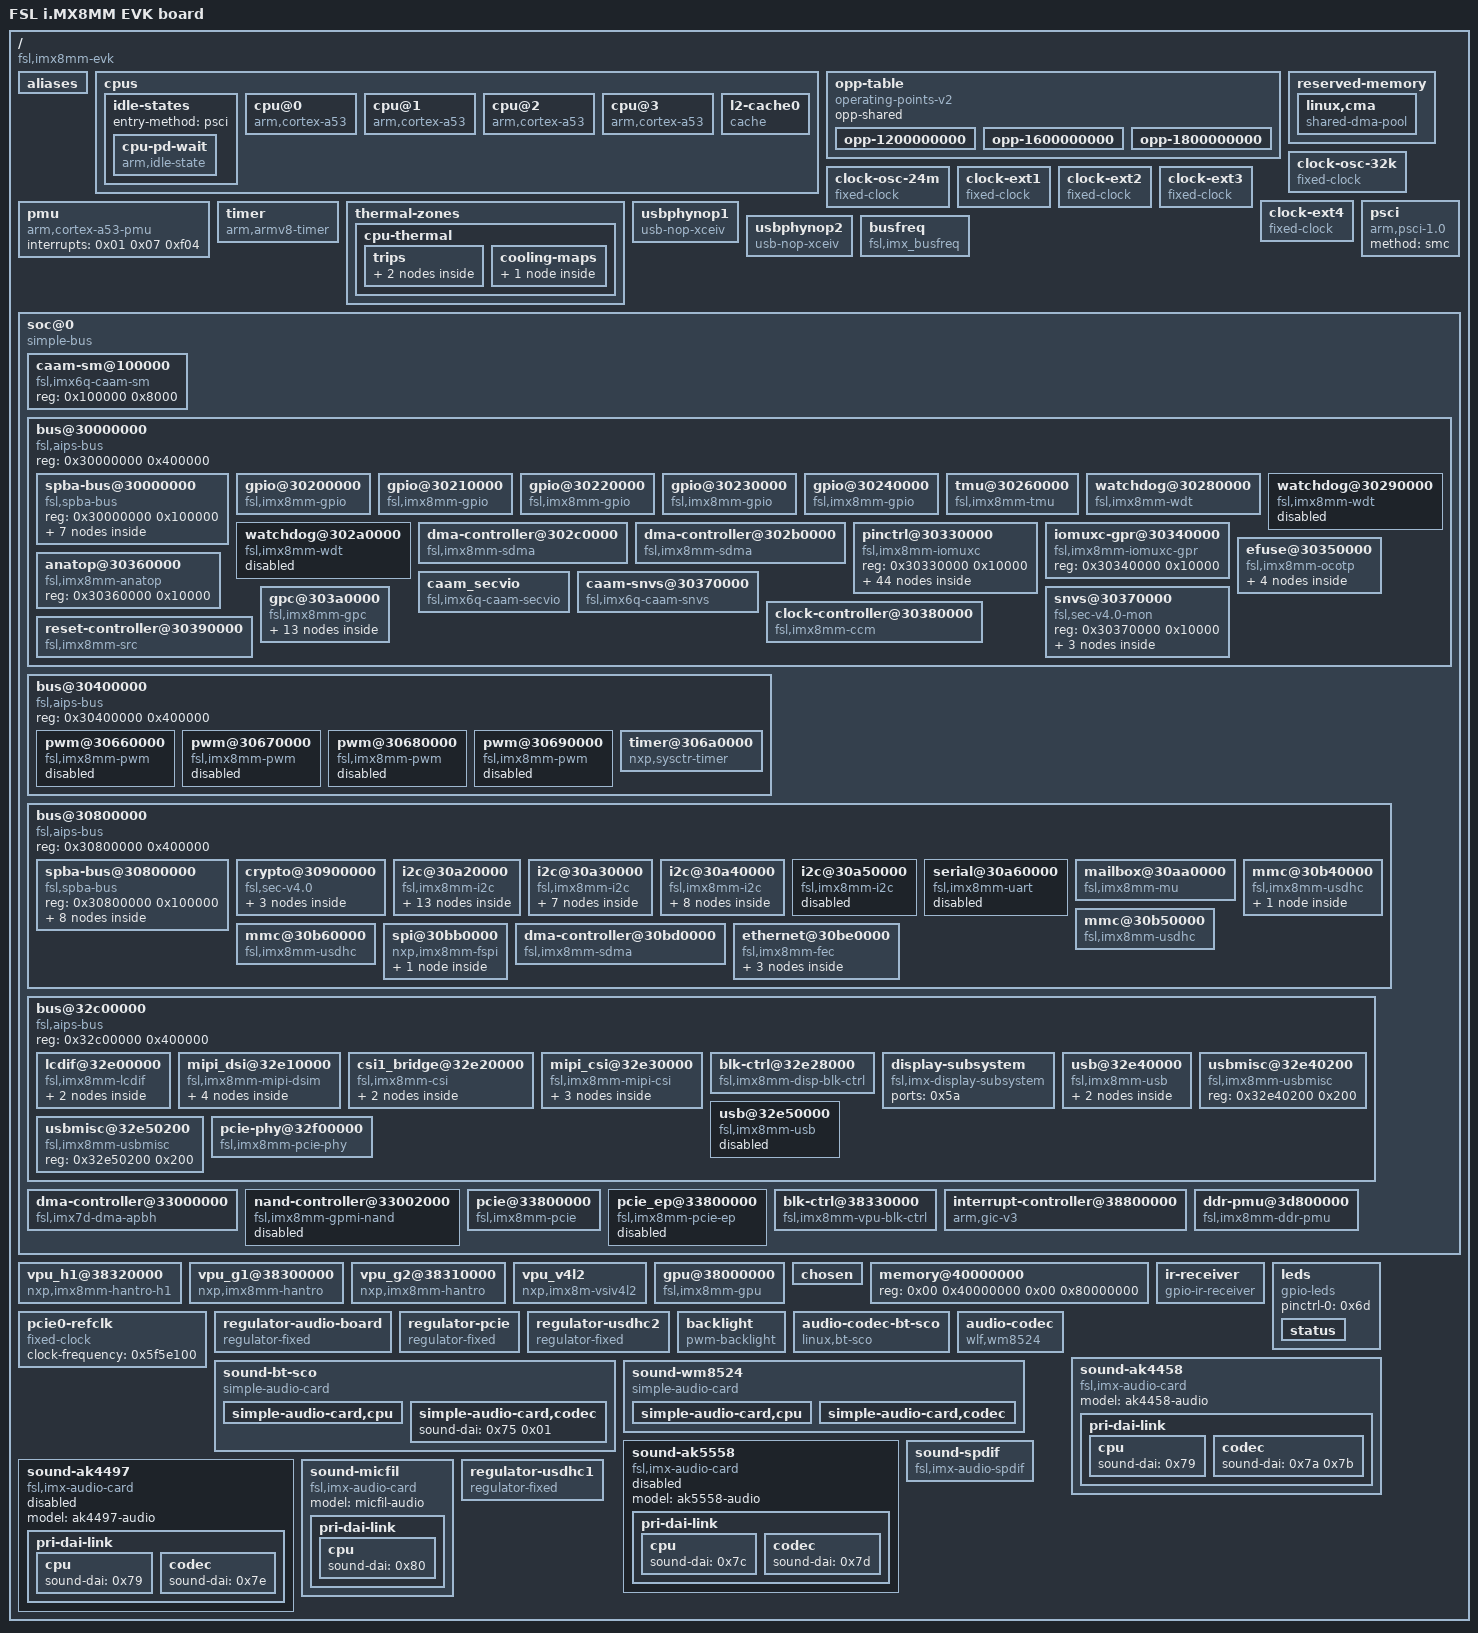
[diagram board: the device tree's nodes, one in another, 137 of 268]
/dts-v1/;

/ {
	interrupt-parent = <0x01>;
	#address-cells = <0x02>;
	#size-cells = <0x02>;
	model = "FSL i.MX8MM EVK board";
	compatible = "fsl,imx8mm-evk", "fsl,imx8mm";

	aliases {
		ethernet0 = "/soc@0/bus@30800000/ethernet@30be0000";
		gpio0 = "/soc@0/bus@30000000/gpio@30200000";
		gpio1 = "/soc@0/bus@30000000/gpio@30210000";
		gpio2 = "/soc@0/bus@30000000/gpio@30220000";
		gpio3 = "/soc@0/bus@30000000/gpio@30230000";
		gpio4 = "/soc@0/bus@30000000/gpio@30240000";
		i2c0 = "/soc@0/bus@30800000/i2c@30a20000";
		i2c1 = "/soc@0/bus@30800000/i2c@30a30000";
		i2c2 = "/soc@0/bus@30800000/i2c@30a40000";
		i2c3 = "/soc@0/bus@30800000/i2c@30a50000";
		mmc0 = "/soc@0/bus@30800000/mmc@30b40000";
		mmc1 = "/soc@0/bus@30800000/mmc@30b50000";
		mmc2 = "/soc@0/bus@30800000/mmc@30b60000";
		sai1 = "/soc@0/bus@30000000/spba-bus@30000000/sai@30010000";
		sai2 = "/soc@0/bus@30000000/spba-bus@30000000/sai@30020000";
		sai3 = "/soc@0/bus@30000000/spba-bus@30000000/sai@30030000";
		sai5 = "/soc@0/bus@30000000/spba-bus@30000000/sai@30050000";
		sai6 = "/soc@0/bus@30000000/spba-bus@30000000/sai@30060000";
		serial0 = "/soc@0/bus@30800000/spba-bus@30800000/serial@30860000";
		serial1 = "/soc@0/bus@30800000/spba-bus@30800000/serial@30890000";
		serial2 = "/soc@0/bus@30800000/spba-bus@30800000/serial@30880000";
		serial3 = "/soc@0/bus@30800000/serial@30a60000";
		spi0 = "/soc@0/bus@30800000/spi@30bb0000";
		spi1 = "/soc@0/bus@30800000/spba-bus@30800000/spi@30830000";
		spi2 = "/soc@0/bus@30800000/spba-bus@30800000/spi@30840000";
	};

	cpus {
		#address-cells = <0x01>;
		#size-cells = <0x00>;

		idle-states {
			entry-method = "psci";

			cpu-pd-wait {
				compatible = "arm,idle-state";
				arm,psci-suspend-param = <0x10033>;
				local-timer-stop;
				entry-latency-us = <0x3e8>;
				exit-latency-us = <0x2bc>;
				min-residency-us = <0xa8c>;
				phandle = <0x06>;
			};
		};

		cpu@0 {
			device_type = "cpu";
			compatible = "arm,cortex-a53";
			reg = <0x00>;
			clock-latency = <0xee6c>;
			clocks = <0x02 0xd7>;
			enable-method = "psci";
			i-cache-size = <0x8000>;
			i-cache-line-size = <0x40>;
			i-cache-sets = <0x100>;
			d-cache-size = <0x8000>;
			d-cache-line-size = <0x40>;
			d-cache-sets = <0x80>;
			next-level-cache = <0x03>;
			operating-points-v2 = <0x04>;
			nvmem-cells = <0x05>;
			nvmem-cell-names = "speed_grade";
			cpu-idle-states = <0x06>;
			#cooling-cells = <0x02>;
			cpu-supply = <0x07>;
			phandle = <0x0a>;
		};

		cpu@1 {
			device_type = "cpu";
			compatible = "arm,cortex-a53";
			reg = <0x01>;
			clock-latency = <0xee6c>;
			clocks = <0x02 0xd7>;
			enable-method = "psci";
			i-cache-size = <0x8000>;
			i-cache-line-size = <0x40>;
			i-cache-sets = <0x100>;
			d-cache-size = <0x8000>;
			d-cache-line-size = <0x40>;
			d-cache-sets = <0x80>;
			next-level-cache = <0x03>;
			operating-points-v2 = <0x04>;
			cpu-idle-states = <0x06>;
			#cooling-cells = <0x02>;
			cpu-supply = <0x07>;
			phandle = <0x0b>;
		};

		cpu@2 {
			device_type = "cpu";
			compatible = "arm,cortex-a53";
			reg = <0x02>;
			clock-latency = <0xee6c>;
			clocks = <0x02 0xd7>;
			enable-method = "psci";
			i-cache-size = <0x8000>;
			i-cache-line-size = <0x40>;
			i-cache-sets = <0x100>;
			d-cache-size = <0x8000>;
			d-cache-line-size = <0x40>;
			d-cache-sets = <0x80>;
			next-level-cache = <0x03>;
			operating-points-v2 = <0x04>;
			cpu-idle-states = <0x06>;
			#cooling-cells = <0x02>;
			cpu-supply = <0x07>;
			phandle = <0x0c>;
		};

		cpu@3 {
			device_type = "cpu";
			compatible = "arm,cortex-a53";
			reg = <0x03>;
			clock-latency = <0xee6c>;
			clocks = <0x02 0xd7>;
			enable-method = "psci";
			i-cache-size = <0x8000>;
			i-cache-line-size = <0x40>;
			i-cache-sets = <0x100>;
			d-cache-size = <0x8000>;
			d-cache-line-size = <0x40>;
			d-cache-sets = <0x80>;
			next-level-cache = <0x03>;
			operating-points-v2 = <0x04>;
			cpu-idle-states = <0x06>;
			#cooling-cells = <0x02>;
			cpu-supply = <0x07>;
			phandle = <0x0d>;
		};

		l2-cache0 {
			compatible = "cache";
			cache-level = <0x02>;
			cache-size = <0x80000>;
			cache-line-size = <0x40>;
			cache-sets = <0x200>;
			phandle = <0x03>;
		};
	};

	opp-table {
		compatible = "operating-points-v2";
		opp-shared;
		phandle = <0x04>;

		opp-1200000000 {
			opp-hz = <0x00 0x47868c00>;
			opp-microvolt = <0xcf850>;
			opp-supported-hw = <0x0e 0x07>;
			clock-latency-ns = <0x249f0>;
			opp-suspend;
		};

		opp-1600000000 {
			opp-hz = <0x00 0x5f5e1000>;
			opp-microvolt = <0xe7ef0>;
			opp-supported-hw = <0x0c 0x07>;
			clock-latency-ns = <0x249f0>;
			opp-suspend;
		};

		opp-1800000000 {
			opp-hz = <0x00 0x6b49d200>;
			opp-microvolt = <0xf4240>;
			opp-supported-hw = <0x08 0x03>;
			clock-latency-ns = <0x249f0>;
			opp-suspend;
		};
	};

	reserved-memory {
		#address-cells = <0x02>;
		#size-cells = <0x02>;
		ranges;

		linux,cma {
			compatible = "shared-dma-pool";
			reusable;
			size = <0x00 0x28000000>;
			alloc-ranges = <0x00 0x80000000 0x00 0x40000000>;
			linux,cma-default;
		};
	};

	clock-osc-32k {
		compatible = "fixed-clock";
		#clock-cells = <0x00>;
		clock-frequency = <0x8000>;
		clock-output-names = "osc_32k";
		phandle = <0x1c>;
	};

	clock-osc-24m {
		compatible = "fixed-clock";
		#clock-cells = <0x00>;
		clock-frequency = <0x16e3600>;
		clock-output-names = "osc_24m";
		phandle = <0x1d>;
	};

	clock-ext1 {
		compatible = "fixed-clock";
		#clock-cells = <0x00>;
		clock-frequency = <0x7ed6b40>;
		clock-output-names = "clk_ext1";
		phandle = <0x1e>;
	};

	clock-ext2 {
		compatible = "fixed-clock";
		#clock-cells = <0x00>;
		clock-frequency = <0x7ed6b40>;
		clock-output-names = "clk_ext2";
		phandle = <0x1f>;
	};

	clock-ext3 {
		compatible = "fixed-clock";
		#clock-cells = <0x00>;
		clock-frequency = <0x7ed6b40>;
		clock-output-names = "clk_ext3";
		phandle = <0x20>;
	};

	clock-ext4 {
		compatible = "fixed-clock";
		#clock-cells = <0x00>;
		clock-frequency = <0x7ed6b40>;
		clock-output-names = "clk_ext4";
		phandle = <0x21>;
	};

	psci {
		compatible = "arm,psci-1.0";
		method = "smc";
	};

	pmu {
		compatible = "arm,cortex-a53-pmu";
		interrupts = <0x01 0x07 0xf04>;
	};

	timer {
		compatible = "arm,armv8-timer";
		interrupts = <0x01 0x0d 0xf08 0x01 0x0e 0xf08 0x01 0x0b 0xf08 0x01 0x0a 0xf08>;
		clock-frequency = <0x7a1200>;
		arm,no-tick-in-suspend;
	};

	thermal-zones {

		cpu-thermal {
			polling-delay-passive = <0xfa>;
			polling-delay = <0x7d0>;
			thermal-sensors = <0x08>;

			trips {

				trip0 {
					temperature = <0x14c08>;
					hysteresis = <0x7d0>;
					type = "passive";
					phandle = <0x09>;
				};

				trip1 {
					temperature = <0x17318>;
					hysteresis = <0x7d0>;
					type = "critical";
				};
			};

			cooling-maps {

				map0 {
					trip = <0x09>;
					cooling-device = <0x0a 0xffffffff 0xffffffff 0x0b 0xffffffff 0xffffffff 0x0c 0xffffffff 0xffffffff 0x0d 0xffffffff 0xffffffff>;
				};
			};
		};
	};

	usbphynop1 {
		#phy-cells = <0x00>;
		compatible = "usb-nop-xceiv";
		clocks = <0x02 0x84>;
		assigned-clocks = <0x02 0x84>;
		assigned-clock-parents = <0x02 0x32>;
		clock-names = "main_clk";
		power-domains = <0x0e>;
		wakeup-source;
		phandle = <0x5b>;
	};

	usbphynop2 {
		#phy-cells = <0x00>;
		compatible = "usb-nop-xceiv";
		clocks = <0x02 0x84>;
		assigned-clocks = <0x02 0x84>;
		assigned-clock-parents = <0x02 0x32>;
		clock-names = "main_clk";
		power-domains = <0x0f>;
		wakeup-source;
		phandle = <0x5e>;
	};

	busfreq {
		compatible = "fsl,imx_busfreq";
		clocks = <0x02 0x29 0x02 0x61 0x02 0x62 0x02 0x62 0x02 0xdc 0x02 0xdd 0x02 0x30 0x02 0x32 0x02 0x3f 0x02 0x5b 0x02 0x5d 0x02 0x51 0x02 0x02 0x02 0x38 0x02 0x15>;
		clock-names = "dram_pll", "dram_alt_src", "dram_apb_src", "dram_apb_pre_div", "dram_core", "dram_alt_root", "sys_pll1_40m", "sys_pll1_100m", "sys_pll2_333m", "noc_div", "ahb_div", "main_axi_src", "osc_24m", "sys_pll1_800m", "dram_pll_div";
		interrupts = <0x00 0x4a 0x04 0x00 0x4b 0x04 0x00 0x4c 0x04 0x00 0x4d 0x04>;
		interrupt-name = "irq_busfreq_0", "irq_busfreq_1", "irq_busfreq_2", "irq_busfreq_3";
	};

	soc@0 {
		compatible = "simple-bus";
		#address-cells = <0x01>;
		#size-cells = <0x01>;
		ranges = <0x00 0x00 0x00 0x3e000000>;
		dma-ranges = <0x40000000 0x00 0x40000000 0xc0000000>;
		nvmem-cells = <0x10>;
		nvmem-cell-names = "soc_unique_id";

		caam-sm@100000 {
			compatible = "fsl,imx6q-caam-sm";
			reg = <0x100000 0x8000>;
		};

		bus@30000000 {
			compatible = "fsl,aips-bus", "simple-bus";
			reg = <0x30000000 0x400000>;
			#address-cells = <0x01>;
			#size-cells = <0x01>;
			ranges = <0x30000000 0x30000000 0x400000>;

			spba-bus@30000000 {
				compatible = "fsl,spba-bus", "simple-bus";
				#address-cells = <0x01>;
				#size-cells = <0x01>;
				reg = <0x30000000 0x100000>;
				ranges;

				sai@30010000 {
					#sound-dai-cells = <0x00>;
					compatible = "fsl,imx8mm-sai", "fsl,imx8mq-sai";
					reg = <0x30010000 0x10000>;
					interrupts = <0x00 0x5f 0x04>;
					clocks = <0x02 0xb1 0x02 0x00 0x02 0xb0 0x02 0x00 0x02 0x00 0x02 0x26 0x02 0x27>;
					clock-names = "bus", "mclk0", "mclk1", "mclk2", "mclk3", "pll8k", "pll11k";
					dmas = <0x11 0x00 0x19 0x00 0x11 0x01 0x19 0x00>;
					dma-names = "rx", "tx";
					fsl,dataline = <0x00 0xff 0xff 0x02 0xff 0x11>;
					status = "okay";
					pinctrl-names = "default", "dsd";
					pinctrl-0 = <0x12>;
					pinctrl-1 = <0x13>;
					assigned-clocks = <0x02 0x6c>;
					assigned-clock-parents = <0x02 0x26>;
					assigned-clock-rates = <0x2ee0000>;
					fsl,sai-multi-lane;
					fsl,sai-mclk-direction-output;
					phandle = <0x79>;
				};

				sai@30020000 {
					#sound-dai-cells = <0x00>;
					compatible = "fsl,imx8mm-sai", "fsl,imx8mq-sai";
					reg = <0x30020000 0x10000>;
					interrupts = <0x00 0x60 0x04>;
					clocks = <0x02 0xb3 0x02 0x00 0x02 0xb2 0x02 0x00 0x02 0x00>;
					clock-names = "bus", "mclk0", "mclk1", "mclk2", "mclk3";
					dmas = <0x11 0x02 0x02 0x00 0x11 0x03 0x02 0x00>;
					dma-names = "rx", "tx";
					status = "okay";
					pinctrl-names = "default";
					pinctrl-0 = <0x14>;
					assigned-clocks = <0x02 0x6d>;
					assigned-clock-parents = <0x02 0x26>;
					assigned-clock-rates = <0x1770000>;
					fsl,sai-mclk-direction-output;
					phandle = <0x74>;
				};

				sai@30030000 {
					#sound-dai-cells = <0x00>;
					compatible = "fsl,imx8mm-sai", "fsl,imx8mq-sai";
					reg = <0x30030000 0x10000>;
					interrupts = <0x00 0x32 0x04>;
					clocks = <0x02 0xb5 0x02 0x00 0x02 0xb4 0x02 0x00 0x02 0x00>;
					clock-names = "bus", "mclk0", "mclk1", "mclk2", "mclk3";
					dmas = <0x11 0x04 0x02 0x00 0x11 0x05 0x02 0x00>;
					dma-names = "rx", "tx";
					status = "okay";
					pinctrl-names = "default";
					pinctrl-0 = <0x15>;
					assigned-clocks = <0x02 0x6e>;
					assigned-clock-parents = <0x02 0x26>;
					assigned-clock-rates = <0x1770000>;
					fsl,sai-mclk-direction-output;
					phandle = <0x77>;
				};

				sai@30050000 {
					#sound-dai-cells = <0x00>;
					compatible = "fsl,imx8mm-sai", "fsl,imx8mq-sai";
					reg = <0x30050000 0x10000>;
					interrupts = <0x00 0x5a 0x04>;
					clocks = <0x02 0xb9 0x02 0x00 0x02 0xb8 0x02 0x00 0x02 0x00 0x02 0x26 0x02 0x27>;
					clock-names = "bus", "mclk0", "mclk1", "mclk2", "mclk3", "pll8k", "pll11k";
					dmas = <0x11 0x08 0x19 0x00 0x11 0x09 0x19 0x00>;
					dma-names = "rx", "tx";
					fsl,dataline = <0x00 0x0f 0x0f>;
					status = "disabled";
					pinctrl-names = "default";
					pinctrl-0 = <0x16>;
					assigned-clocks = <0x02 0x70>;
					assigned-clock-parents = <0x02 0x26>;
					assigned-clock-rates = <0x2ee0000>;
					fsl,sai-asynchronous;
					fsl,sai-multi-lane;
					fsl,sai-mclk-direction-output;
					phandle = <0x7c>;
				};

				sai@30060000 {
					#sound-dai-cells = <0x00>;
					compatible = "fsl,imx8mm-sai", "fsl,imx8mq-sai";
					reg = <0x30060000 0x10000>;
					interrupts = <0x00 0x5a 0x04>;
					clocks = <0x02 0xbb 0x02 0x00 0x02 0xba 0x02 0x00 0x02 0x00>;
					clock-names = "bus", "mclk0", "mclk1", "mclk2", "mclk3";
					dmas = <0x11 0x0a 0x02 0x00 0x11 0x0b 0x02 0x00>;
					dma-names = "rx", "tx";
					status = "okay";
					fsl,sai-monitor-spdif;
					fsl,sai-asynchronous;
				};

				audio-controller@30080000 {
					compatible = "fsl,imx8mm-micfil";
					reg = <0x30080000 0x10000>;
					interrupts = <0x00 0x6d 0x04 0x00 0x6e 0x04 0x00 0x2c 0x04 0x00 0x2d 0x04>;
					clocks = <0x02 0xd8 0x02 0xcb 0x02 0x26 0x02 0x27 0x02 0x06>;
					clock-names = "ipg_clk", "ipg_clk_app", "pll8k", "pll11k", "clkext3";
					dmas = <0x11 0x18 0x19 0x80000000>;
					dma-names = "rx";
					status = "okay";
					#sound-dai-cells = <0x00>;
					pinctrl-names = "default";
					pinctrl-0 = <0x17>;
					assigned-clocks = <0x02 0x9c>;
					assigned-clock-parents = <0x02 0x26>;
					assigned-clock-rates = <0xbb80000>;
					phandle = <0x80>;
				};

				spdif@30090000 {
					compatible = "fsl,imx35-spdif";
					reg = <0x30090000 0x10000>;
					interrupts = <0x00 0x06 0x04>;
					clocks = <0x02 0x5e 0x02 0x02 0x02 0x72 0x02 0x00 0x02 0x00 0x02 0x00 0x02 0x5e 0x02 0x00 0x02 0x00 0x02 0x00 0x02 0x26 0x02 0x27>;
					clock-names = "core", "rxtx0", "rxtx1", "rxtx2", "rxtx3", "rxtx4", "rxtx5", "rxtx6", "rxtx7", "spba", "pll8k", "pll11k";
					dmas = <0x11 0x1c 0x12 0x00 0x11 0x1d 0x12 0x00>;
					dma-names = "rx", "tx";
					status = "okay";
					pinctrl-names = "default";
					pinctrl-0 = <0x18>;
					assigned-clocks = <0x02 0x72>;
					assigned-clock-parents = <0x02 0x26>;
					assigned-clock-rates = <0x1770000>;
					phandle = <0x7f>;
				};
			};

			gpio@30200000 {
				compatible = "fsl,imx8mm-gpio", "fsl,imx35-gpio";
				reg = <0x30200000 0x10000>;
				interrupts = <0x00 0x40 0x04 0x00 0x41 0x04>;
				clocks = <0x02 0xdf>;
				gpio-controller;
				#gpio-cells = <0x02>;
				interrupt-controller;
				#interrupt-cells = <0x02>;
				gpio-ranges = <0x19 0x00 0x0a 0x1e>;
				phandle = <0x2f>;
			};

			gpio@30210000 {
				compatible = "fsl,imx8mm-gpio", "fsl,imx35-gpio";
				reg = <0x30210000 0x10000>;
				interrupts = <0x00 0x42 0x04 0x00 0x43 0x04>;
				clocks = <0x02 0xe0>;
				gpio-controller;
				#gpio-cells = <0x02>;
				interrupt-controller;
				#interrupt-cells = <0x02>;
				gpio-ranges = <0x19 0x00 0x28 0x15>;
				phandle = <0x34>;
			};

			gpio@30220000 {
				compatible = "fsl,imx8mm-gpio", "fsl,imx35-gpio";
				reg = <0x30220000 0x10000>;
				interrupts = <0x00 0x44 0x04 0x00 0x45 0x04>;
				clocks = <0x02 0xe1>;
				gpio-controller;
				#gpio-cells = <0x02>;
				interrupt-controller;
				#interrupt-cells = <0x02>;
				gpio-ranges = <0x19 0x00 0x3d 0x1a>;
				phandle = <0x6e>;
			};

			gpio@30230000 {
				compatible = "fsl,imx8mm-gpio", "fsl,imx35-gpio";
				reg = <0x30230000 0x10000>;
				interrupts = <0x00 0x46 0x04 0x00 0x47 0x04>;
				clocks = <0x02 0xe2>;
				gpio-controller;
				#gpio-cells = <0x02>;
				interrupt-controller;
				#interrupt-cells = <0x02>;
				gpio-ranges = <0x19 0x00 0x57 0x20>;
				phandle = <0x4f>;
			};

			gpio@30240000 {
				compatible = "fsl,imx8mm-gpio", "fsl,imx35-gpio";
				reg = <0x30240000 0x10000>;
				interrupts = <0x00 0x48 0x04 0x00 0x49 0x04>;
				clocks = <0x02 0xe3>;
				gpio-controller;
				#gpio-cells = <0x02>;
				interrupt-controller;
				#interrupt-cells = <0x02>;
				gpio-ranges = <0x19 0x00 0x77 0x1e>;
				phandle = <0x29>;
			};

			tmu@30260000 {
				compatible = "fsl,imx8mm-tmu";
				reg = <0x30260000 0x10000>;
				clocks = <0x02 0xd1>;
				#thermal-sensor-cells = <0x00>;
				phandle = <0x08>;
			};

			watchdog@30280000 {
				compatible = "fsl,imx8mm-wdt", "fsl,imx21-wdt";
				reg = <0x30280000 0x10000>;
				interrupts = <0x00 0x4e 0x04>;
				clocks = <0x02 0xc4>;
				status = "okay";
				pinctrl-names = "default";
				pinctrl-0 = <0x1a>;
				fsl,ext-reset-output;
			};

			watchdog@30290000 {
				compatible = "fsl,imx8mm-wdt", "fsl,imx21-wdt";
				reg = <0x30290000 0x10000>;
				interrupts = <0x00 0x4f 0x04>;
				clocks = <0x02 0xc5>;
				status = "disabled";
			};

			watchdog@302a0000 {
				compatible = "fsl,imx8mm-wdt", "fsl,imx21-wdt";
				reg = <0x302a0000 0x10000>;
				interrupts = <0x00 0x0a 0x04>;
				clocks = <0x02 0xc6>;
				status = "disabled";
			};

			dma-controller@302c0000 {
				compatible = "fsl,imx8mm-sdma", "fsl,imx8mq-sdma";
				reg = <0x302c0000 0x10000>;
				interrupts = <0x00 0x67 0x04>;
				clocks = <0x02 0xd4 0x02 0xd4>;
				clock-names = "ipg", "ahb";
				#dma-cells = <0x03>;
				fsl,sdma-ram-script-name = "imx/sdma/sdma-imx7d.bin";
				phandle = <0x11>;
			};

			dma-controller@302b0000 {
				compatible = "fsl,imx8mm-sdma", "fsl,imx8mq-sdma";
				reg = <0x302b0000 0x10000>;
				interrupts = <0x00 0x22 0x04>;
				clocks = <0x02 0xd5 0x02 0xd5>;
				clock-names = "ipg", "ahb";
				#dma-cells = <0x03>;
				fsl,sdma-ram-script-name = "imx/sdma/sdma-imx7d.bin";
			};

			pinctrl@30330000 {
				compatible = "fsl,imx8mm-iomuxc";
				reg = <0x30330000 0x10000>;
				phandle = <0x19>;

				ir-recv {
					fsl,pins = <0x5c 0x2c4 0x00 0x00 0x00 0x4f>;
				};

				csi_pwn_grp {
					fsl,pins = <0x44 0x2ac 0x00 0x00 0x00 0x19>;
					phandle = <0x3a>;
				};

				csi_rst_grp {
					fsl,pins = <0x40 0x2a8 0x00 0x00 0x00 0x19 0x60 0x2c8 0x00 0x06 0x00 0x59>;
					phandle = <0x3b>;
				};

				ecspi2grp {
					fsl,pins = <0x204 0x46c 0x00 0x00 0x00 0x82 0x208 0x470 0x00 0x00 0x00 0x82 0x20c 0x474 0x00 0x00 0x00 0x82>;
					phandle = <0x27>;
				};

				ecspi2cs {
					fsl,pins = <0x210 0x478 0x00 0x05 0x00 0x40000>;
					phandle = <0x28>;
				};

				fec1grp {
					fsl,pins = <0x68 0x2d0 0x00 0x00 0x00 0x03 0x6c 0x2d4 0x4c0 0x00 0x01 0x03 0x70 0x2d8 0x00 0x00 0x00 0x1f 0x74 0x2dc 0x00 0x00 0x00 0x1f 0x78 0x2e0 0x00 0x00 0x00 0x1f 0x7c 0x2e4 0x00 0x00 0x00 0x1f 0x9c 0x304 0x00 0x00 0x00 0x91 0x98 0x300 0x00 0x00 0x00 0x91 0x94 0x2fc 0x00 0x00 0x00 0x91 0x90 0x2f8 0x00 0x00 0x00 0x91 0x84 0x2ec 0x00 0x00 0x00 0x1f 0x8c 0x2f4 0x00 0x00 0x00 0x91 0x88 0x2f0 0x00 0x00 0x00 0x91 0x80 0x2e8 0x00 0x00 0x00 0x1f 0x1b4 0x41c 0x00 0x05 0x00 0x19>;
					phandle = <0x4d>;
				};

				gpioledgrp {
					fsl,pins = <0x134 0x39c 0x00 0x05 0x00 0x19>;
					phandle = <0x6d>;
				};

				irgrp {
					fsl,pins = <0x5c 0x2c4 0x00 0x00 0x00 0x4f>;
					phandle = <0x6c>;
				};

				gpiowlfgrp {
					fsl,pins = <0x230 0x498 0x00 0x05 0x00 0xd6>;
					phandle = <0x72>;
				};

				i2c1grp {
					fsl,pins = <0x214 0x47c 0x00 0x00 0x00 0x400001c3 0x218 0x480 0x00 0x00 0x00 0x400001c3>;
					phandle = <0x2d>;
				};

				i2c2grp {
					fsl,pins = <0x21c 0x484 0x00 0x00 0x00 0x400001c3 0x220 0x488 0x00 0x00 0x00 0x400001c3>;
					phandle = <0x30>;
				};

				synaptics_dsx_iogrp {
					fsl,pins = <0x4c 0x2b4 0x00 0x00 0x00 0x19>;
					phandle = <0x31>;
				};

				i2c3grp {
					fsl,pins = <0x224 0x48c 0x00 0x00 0x00 0x400001c3 0x228 0x490 0x00 0x00 0x00 0x400001c3>;
					phandle = <0x36>;
				};

				mipi_dsi_en {
					fsl,pins = <0x48 0x2b0 0x00 0x00 0x00 0x16>;
				};

				pcie0grp {
					fsl,pins = <0x22c 0x494 0x524 0x12 0x00 0x61 0x1b0 0x418 0x00 0x05 0x00 0x41>;
					phandle = <0x64>;
				};

				pcie0reggrp {
					fsl,pins = <0x3c 0x2a4 0x00 0x00 0x00 0x41>;
					phandle = <0x6f>;
				};

				pdmgrp {
					fsl,pins = <0x158 0x3c0 0x52c 0x00 0x00 0xd6 0x144 0x3ac 0x00 0x04 0x00 0xd6 0x140 0x3a8 0x4e4 0x00 0x00 0xd6 0x148 0x3b0 0x534 0x04 0x00 0xd6 0x14c 0x3b4 0x538 0x04 0x00 0xd6 0x150 0x3b8 0x53c 0x04 0x00 0xd6 0x154 0x3bc 0x540 0x04 0x00 0xd6>;
					phandle = <0x17>;
				};

				pmicirqgrp {
					fsl,pins = <0x34 0x29c 0x00 0x00 0x00 0x141>;
					phandle = <0x2e>;
				};

				regusdhc2vmmcgrp {
					fsl,pins = <0xec 0x354 0x00 0x05 0x00 0x41>;
					phandle = <0x70>;
				};

				sai1grp {
					fsl,pins = <0x1ac 0x414 0x00 0x00 0x00 0xd6 0x184 0x3ec 0x4cc 0x00 0x03 0xd6 0x180 0x3e8 0x4cc 0x02 0x04 0xd6 0x188 0x3f0 0x4c8 0x00 0x01 0xd6 0x18c 0x3f4 0x00 0x00 0x00 0xd6 0x190 0x3f8 0x00 0x00 0x00 0xd6 0x194 0x3fc 0x00 0x00 0x00 0xd6 0x198 0x400 0x00 0x00 0x00 0xd6 0x19c 0x404 0x00 0x00 0x00 0xd6 0x1a0 0x408 0x00 0x00 0x00 0xd6 0x1a4 0x40c 0x00 0x00 0x00 0xd6 0x1a8 0x410 0x00 0x00 0x00 0xd6>;
					phandle = <0x12>;
				};

				sai1grp_dsd {
					fsl,pins = <0x1ac 0x414 0x00 0x00 0x00 0xd6 0x184 0x3ec 0x4cc 0x00 0x03 0xd6 0x180 0x3e8 0x00 0x03 0x00 0xd6 0x188 0x3f0 0x4c8 0x00 0x01 0xd6 0x18c 0x3f4 0x00 0x00 0x00 0xd6 0x190 0x3f8 0x00 0x00 0x00 0xd6 0x194 0x3fc 0x00 0x00 0x00 0xd6 0x198 0x400 0x00 0x00 0x00 0xd6 0x19c 0x404 0x00 0x00 0x00 0xd6 0x1a0 0x408 0x00 0x00 0x00 0xd6 0x1a4 0x40c 0x00 0x00 0x00 0xd6 0x1a8 0x410 0x00 0x00 0x00 0xd6>;
					phandle = <0x13>;
				};

				sai2grp {
					fsl,pins = <0x1c0 0x428 0x00 0x00 0x00 0xd6 0x1bc 0x424 0x00 0x00 0x00 0xd6 0x1c4 0x42c 0x00 0x00 0x00 0xd6 0x1b8 0x420 0x00 0x00 0x00 0xd6>;
					phandle = <0x14>;
				};

				sai3grp {
					fsl,pins = <0x1d8 0x440 0x00 0x00 0x00 0xd6 0x1dc 0x444 0x00 0x00 0x00 0xd6 0x1e4 0x44c 0x00 0x00 0x00 0xd6 0x1e0 0x448 0x00 0x00 0x00 0xd6>;
					phandle = <0x15>;
				};

				sai5grp {
					fsl,pins = <0x158 0x3c0 0x52c 0x00 0x00 0xd6 0x144 0x3ac 0x4d0 0x00 0x00 0xd6 0x140 0x3a8 0x4e4 0x00 0x00 0xd6 0x148 0x3b0 0x4d4 0x00 0x00 0xd6 0x14c 0x3b4 0x4d8 0x00 0x00 0xd6 0x150 0x3b8 0x4dc 0x00 0x00 0xd6 0x154 0x3bc 0x4e0 0x00 0x00 0xd6>;
					phandle = <0x16>;
				};

				spdif1grp {
					fsl,pins = <0x1e8 0x450 0x00 0x00 0x00 0xd6 0x1ec 0x454 0x00 0x00 0x00 0xd6>;
					phandle = <0x18>;
				};

				typec1grp {
					fsl,pins = <0xcc 0x334 0x00 0x05 0x00 0x159>;
					phandle = <0x33>;
				};

				uart1grp {
					fsl,pins = <0x234 0x49c 0x4f4 0x00 0x00 0x140 0x238 0x4a0 0x00 0x00 0x00 0x140 0x244 0x4ac 0x00 0x01 0x00 0x140 0x248 0x4b0 0x4f0 0x01 0x01 0x140>;
					phandle = <0x2a>;
				};

				uart2grp {
					fsl,pins = <0x23c 0x4a4 0x4fc 0x00 0x00 0x140 0x240 0x4a8 0x00 0x00 0x00 0x140>;
					phandle = <0x2c>;
				};

				uart3grp {
					fsl,pins = <0x1f4 0x45c 0x504 0x01 0x00 0x140 0x1f8 0x460 0x00 0x01 0x00 0x140 0x200 0x468 0x500 0x01 0x01 0x140 0x1fc 0x464 0x00 0x01 0x00 0x140>;
					phandle = <0x2b>;
				};

				usdhc1grp {
					fsl,pins = <0xa0 0x308 0x00 0x00 0x00 0x190 0xa4 0x30c 0x00 0x00 0x00 0x1d0 0xa8 0x310 0x00 0x00 0x00 0x1d0 0xac 0x314 0x00 0x00 0x00 0x1d0 0xb0 0x318 0x00 0x00 0x00 0x1d0 0xb4 0x31c 0x00 0x00 0x00 0x1d0>;
					phandle = <0x3d>;
				};

				usdhc1grp100mhz {
					fsl,pins = <0xa0 0x308 0x00 0x00 0x00 0x194 0xa4 0x30c 0x00 0x00 0x00 0x1d4 0xa8 0x310 0x00 0x00 0x00 0x1d4 0xac 0x314 0x00 0x00 0x00 0x1d4 0xb0 0x318 0x00 0x00 0x00 0x1d4 0xb4 0x31c 0x00 0x00 0x00 0x1d4>;
					phandle = <0x3f>;
				};

				usdhc1grp200mhz {
					fsl,pins = <0xa0 0x308 0x00 0x00 0x00 0x196 0xa4 0x30c 0x00 0x00 0x00 0x1d6 0xa8 0x310 0x00 0x00 0x00 0x1d6 0xac 0x314 0x00 0x00 0x00 0x1d6 0xb0 0x318 0x00 0x00 0x00 0x1d6 0xb4 0x31c 0x00 0x00 0x00 0x1d6>;
					phandle = <0x40>;
				};

				usdhc2grpgpiogrp {
					fsl,pins = <0x64 0x2cc 0x00 0x00 0x00 0x1c4>;
					phandle = <0x43>;
				};

				usdhc2grp {
					fsl,pins = <0xd4 0x33c 0x00 0x00 0x00 0x190 0xd8 0x340 0x00 0x00 0x00 0x1d0 0xdc 0x344 0x00 0x00 0x00 0x1d0 0xe0 0x348 0x00 0x00 0x00 0x1d0 0xe4 0x34c 0x00 0x00 0x00 0x1d0 0xe8 0x350 0x00 0x00 0x00 0x1d0 0x38 0x2a0 0x00 0x01 0x00 0x1d0>;
					phandle = <0x42>;
				};

				usdhc2-100mhzgrp {
					fsl,pins = <0xd4 0x33c 0x00 0x00 0x00 0x194 0xd8 0x340 0x00 0x00 0x00 0x1d4 0xdc 0x344 0x00 0x00 0x00 0x1d4 0xe0 0x348 0x00 0x00 0x00 0x1d4 0xe4 0x34c 0x00 0x00 0x00 0x1d4 0xe8 0x350 0x00 0x00 0x00 0x1d4 0x38 0x2a0 0x00 0x01 0x00 0x1d0>;
					phandle = <0x44>;
				};

				usdhc2-200mhzgrp {
					fsl,pins = <0xd4 0x33c 0x00 0x00 0x00 0x196 0xd8 0x340 0x00 0x00 0x00 0x1d6 0xdc 0x344 0x00 0x00 0x00 0x1d6 0xe0 0x348 0x00 0x00 0x00 0x1d6 0xe4 0x34c 0x00 0x00 0x00 0x1d6 0xe8 0x350 0x00 0x00 0x00 0x1d6 0x38 0x2a0 0x00 0x01 0x00 0x1d0>;
					phandle = <0x45>;
				};

				wdoggrp {
					fsl,pins = <0x30 0x298 0x00 0x01 0x00 0x166>;
					phandle = <0x1a>;
				};

				backlightgrp {
					fsl,pins = <0x2c 0x294 0x00 0x01 0x00 0x06>;
					phandle = <0x25>;
				};

				regusdhc1vmmcgrp {
					fsl,pins = <0xc8 0x330 0x00 0x05 0x00 0x141>;
					phandle = <0x81>;
				};

				flexspigrp {
					fsl,pins = <0xf4 0x35c 0x00 0x01 0x00 0x1c2 0xf8 0x360 0x00 0x01 0x00 0x82 0x10c 0x374 0x00 0x01 0x00 0x82 0x110 0x378 0x00 0x01 0x00 0x82 0x114 0x37c 0x00 0x01 0x00 0x82 0x118 0x380 0x00 0x01 0x00 0x82>;
					phandle = <0x4a>;
				};

				usdhc3grp {
					fsl,pins = <0x138 0x3a0 0x00 0x12 0x00 0x190 0x13c 0x3a4 0x00 0x02 0x00 0x1d0 0x11c 0x384 0x00 0x02 0x00 0x1d0 0x120 0x388 0x00 0x02 0x00 0x1d0 0x124 0x38c 0x00 0x02 0x00 0x1d0 0x124 0x38c 0x00 0x02 0x00 0x1d0 0x128 0x390 0x00 0x02 0x00 0x1d0 0x130 0x398 0x00 0x02 0x00 0x1d0 0x100 0x368 0x00 0x02 0x00 0x1d0 0x104 0x36c 0x00 0x02 0x00 0x1d0 0x108 0x370 0x00 0x02 0x00 0x1d0 0xfc 0x364 0x00 0x02 0x00 0x190>;
					phandle = <0x47>;
				};

				usdhc3-100mhzgrp {
					fsl,pins = <0x138 0x3a0 0x00 0x12 0x00 0x194 0x13c 0x3a4 0x00 0x02 0x00 0x1d4 0x11c 0x384 0x00 0x02 0x00 0x1d4 0x120 0x388 0x00 0x02 0x00 0x1d4 0x124 0x38c 0x00 0x02 0x00 0x1d4 0x128 0x390 0x00 0x02 0x00 0x1d4 0x130 0x398 0x00 0x02 0x00 0x1d4 0x100 0x368 0x00 0x02 0x00 0x1d4 0x104 0x36c 0x00 0x02 0x00 0x1d4 0x108 0x370 0x00 0x02 0x00 0x1d4 0xfc 0x364 0x00 0x02 0x00 0x194>;
					phandle = <0x48>;
				};

				usdhc3-200mhzgrp {
					fsl,pins = <0x138 0x3a0 0x00 0x12 0x00 0x196 0x13c 0x3a4 0x00 0x02 0x00 0x1d6 0x11c 0x384 0x00 0x02 0x00 0x1d6 0x120 0x388 0x00 0x02 0x00 0x1d6 0x124 0x38c 0x00 0x02 0x00 0x1d6 0x128 0x390 0x00 0x02 0x00 0x1d6 0x130 0x398 0x00 0x02 0x00 0x1d6 0x100 0x368 0x00 0x02 0x00 0x1d6 0x104 0x36c 0x00 0x02 0x00 0x1d6 0x108 0x370 0x00 0x02 0x00 0x1d6 0xfc 0x364 0x00 0x02 0x00 0x196>;
					phandle = <0x49>;
				};

				wlangrp {
					fsl,pins = <0x28 0x290 0x00 0x05 0x00 0x141 0xc4 0x32c 0x00 0x05 0x00 0x159>;
					phandle = <0x3e>;
				};
			};

			iomuxc-gpr@30340000 {
				compatible = "fsl,imx8mm-iomuxc-gpr", "fsl,imx6q-iomuxc-gpr", "syscon";
				reg = <0x30340000 0x10000>;
				phandle = <0x4c>;
			};

			efuse@30350000 {
				compatible = "fsl,imx8mm-ocotp", "syscon", "simple-mfd";
				reg = <0x30350000 0x10000>;
				clocks = <0x02 0xa8>;
				#address-cells = <0x01>;
				#size-cells = <0x01>;

				unique-id@4 {
					reg = <0x04 0x08>;
					phandle = <0x10>;
				};

				speed-grade@10 {
					reg = <0x10 0x04>;
					phandle = <0x05>;
				};

				mac-address@90 {
					reg = <0x90 0x06>;
					phandle = <0x4b>;
				};

				imx8mm-soc {
					compatible = "fsl,imx8mm-soc";
					nvmem-cells = <0x10>;
					nvmem-cell-names = "soc_unique_id";
				};
			};

			anatop@30360000 {
				compatible = "fsl,imx8mm-anatop", "syscon";
				reg = <0x30360000 0x10000>;
			};

			caam_secvio {
				compatible = "fsl,imx6q-caam-secvio";
				interrupts = <0x00 0x14 0x04>;
				jtag-tamper = "disabled";
				watchdog-tamper = "enabled";
				internal-boot-tamper = "enabled";
				external-pin-tamper = "disabled";
			};

			caam-snvs@30370000 {
				compatible = "fsl,imx6q-caam-snvs";
				reg = <0x30370000 0x10000>;
				clocks = <0x02 0xe4>;
				clock-names = "ipg";
			};

			snvs@30370000 {
				compatible = "fsl,sec-v4.0-mon", "syscon", "simple-mfd";
				reg = <0x30370000 0x10000>;
				phandle = <0x1b>;

				snvs-rtc-lp {
					compatible = "fsl,sec-v4.0-mon-rtc-lp";
					regmap = <0x1b>;
					offset = <0x34>;
					interrupts = <0x00 0x13 0x04 0x00 0x14 0x04>;
					clocks = <0x02 0xe4>;
					clock-names = "snvs-rtc";
				};

				snvs-powerkey {
					compatible = "fsl,sec-v4.0-pwrkey";
					regmap = <0x1b>;
					interrupts = <0x00 0x04 0x04>;
					clocks = <0x02 0xe4>;
					clock-names = "snvs-pwrkey";
					linux,keycode = <0x74>;
					wakeup-source;
					status = "okay";
				};

				snvs-lpgpr {
					compatible = "fsl,imx8mm-snvs-lpgpr", "fsl,imx7d-snvs-lpgpr";
				};
			};

			clock-controller@30380000 {
				compatible = "fsl,imx8mm-ccm";
				reg = <0x30380000 0x10000>;
				#clock-cells = <0x01>;
				clocks = <0x1c 0x1d 0x1e 0x1f 0x20 0x21>;
				clock-names = "osc_32k", "osc_24m", "clk_ext1", "clk_ext2", "clk_ext3", "clk_ext4";
				assigned-clocks = <0x02 0x42 0x02 0xfb 0x02 0x5b 0x02 0x5e 0x02 0x60 0x02 0x1b 0x02 0x14 0x02 0x12 0x02 0x13>;
				assigned-clock-parents = <0x02 0x38 0x02 0x2c 0x02 0x2f 0x02 0x38>;
				assigned-clock-rates = <0x00 0x00 0x00 0x17d78400 0x17d78400 0x2cb41780 0x3df582e0 0x17700000 0x15888000>;
				phandle = <0x02>;
			};

			reset-controller@30390000 {
				compatible = "fsl,imx8mm-src", "fsl,imx8mq-src", "syscon";
				reg = <0x30390000 0x10000>;
				interrupts = <0x00 0x59 0x04>;
				#reset-cells = <0x01>;
				phandle = <0x23>;
			};

			gpc@303a0000 {
				compatible = "fsl,imx8mm-gpc";
				reg = <0x303a0000 0x10000>;
				interrupts = <0x00 0x57 0x04>;
				interrupt-parent = <0x01>;
				interrupt-controller;
				#interrupt-cells = <0x03>;

				pgc {
					#address-cells = <0x01>;
					#size-cells = <0x00>;

					power-domain@0 {
						#power-domain-cells = <0x00>;
						reg = <0x00>;
						clocks = <0x02 0x58>;
						assigned-clocks = <0x02 0x58>;
						assigned-clock-parents = <0x02 0x40>;
						phandle = <0x22>;
					};

					power-domain@1 {
						#power-domain-cells = <0x00>;
						reg = <0x01>;
						power-domains = <0x22>;
						clocks = <0x02 0xa9>;
						phandle = <0x62>;
					};

					power-domain@2 {
						#power-domain-cells = <0x00>;
						reg = <0x02>;
						phandle = <0x0e>;
					};

					power-domain@3 {
						#power-domain-cells = <0x00>;
						reg = <0x03>;
						phandle = <0x0f>;
					};

					power-domain@4 {
						#power-domain-cells = <0x00>;
						reg = <0x04>;
						clocks = <0x02 0xc8 0x02 0x5a>;
						assigned-clocks = <0x02 0x59 0x02 0x5a>;
						assigned-clock-parents = <0x02 0x38 0x02 0x38>;
						assigned-clock-rates = <0x2faf0800 0x17d78400>;
						phandle = <0x24>;
					};

					power-domain@5 {
						#power-domain-cells = <0x00>;
						reg = <0x05>;
						clocks = <0x02 0x5a 0x02 0xc8 0x02 0xd9 0x02 0xc1>;
						resets = <0x23 0x20>;
						power-domains = <0x24>;
						phandle = <0x6b>;
					};

					power-domain@6 {
						#power-domain-cells = <0x00>;
						reg = <0x06>;
						clocks = <0x02 0xd2>;
						assigned-clocks = <0x02 0x54>;
						assigned-clock-parents = <0x02 0x38>;
						phandle = <0x66>;
					};

					power-domain@7 {
						#power-domain-cells = <0x00>;
						reg = <0x07>;
						phandle = <0x67>;
					};

					power-domain@8 {
						#power-domain-cells = <0x00>;
						reg = <0x08>;
						phandle = <0x68>;
					};

					power-domain@9 {
						#power-domain-cells = <0x00>;
						reg = <0x09>;
						phandle = <0x69>;
					};

					power-domain@10 {
						#power-domain-cells = <0x00>;
						reg = <0x0a>;
						clocks = <0x02 0xce 0x02 0xcd>;
						assigned-clocks = <0x02 0x55 0x02 0x56>;
						assigned-clock-parents = <0x02 0x41 0x02 0x38>;
						assigned-clock-rates = <0x1dcd6500 0xbebc200>;
						phandle = <0x58>;
					};

					power-domain@11 {
						#power-domain-cells = <0x00>;
						reg = <0x0b>;
						phandle = <0x59>;
					};
				};
			};
		};

		bus@30400000 {
			compatible = "fsl,aips-bus", "simple-bus";
			reg = <0x30400000 0x400000>;
			#address-cells = <0x01>;
			#size-cells = <0x01>;
			ranges = <0x30400000 0x30400000 0x400000>;

			pwm@30660000 {
				compatible = "fsl,imx8mm-pwm", "fsl,imx27-pwm";
				reg = <0x30660000 0x10000>;
				interrupts = <0x00 0x51 0x04>;
				clocks = <0x02 0xaa 0x02 0xaa>;
				clock-names = "ipg", "per";
				#pwm-cells = <0x03>;
				status = "disabled";
				pinctrl-names = "default";
				pinctrl-0 = <0x25>;
				phandle = <0x71>;
			};

			pwm@30670000 {
				compatible = "fsl,imx8mm-pwm", "fsl,imx27-pwm";
				reg = <0x30670000 0x10000>;
				interrupts = <0x00 0x52 0x04>;
				clocks = <0x02 0xab 0x02 0xab>;
				clock-names = "ipg", "per";
				#pwm-cells = <0x03>;
				status = "disabled";
			};

			pwm@30680000 {
				compatible = "fsl,imx8mm-pwm", "fsl,imx27-pwm";
				reg = <0x30680000 0x10000>;
				interrupts = <0x00 0x53 0x04>;
				clocks = <0x02 0xac 0x02 0xac>;
				clock-names = "ipg", "per";
				#pwm-cells = <0x03>;
				status = "disabled";
			};

			pwm@30690000 {
				compatible = "fsl,imx8mm-pwm", "fsl,imx27-pwm";
				reg = <0x30690000 0x10000>;
				interrupts = <0x00 0x54 0x04>;
				clocks = <0x02 0xad 0x02 0xad>;
				clock-names = "ipg", "per";
				#pwm-cells = <0x03>;
				status = "disabled";
			};

			timer@306a0000 {
				compatible = "nxp,sysctr-timer";
				reg = <0x306a0000 0x20000>;
				interrupts = <0x00 0x2f 0x04>;
				clocks = <0x1d>;
				clock-names = "per";
			};
		};

		bus@30800000 {
			compatible = "fsl,aips-bus", "simple-bus";
			reg = <0x30800000 0x400000>;
			#address-cells = <0x01>;
			#size-cells = <0x01>;
			ranges = <0x30800000 0x30800000 0x400000 0x8000000 0x8000000 0x10000000>;

			spba-bus@30800000 {
				compatible = "fsl,spba-bus", "simple-bus";
				#address-cells = <0x01>;
				#size-cells = <0x01>;
				reg = <0x30800000 0x100000>;
				ranges;

				spi@30820000 {
					compatible = "fsl,imx8mm-ecspi", "fsl,imx51-ecspi";
					#address-cells = <0x01>;
					#size-cells = <0x00>;
					reg = <0x30820000 0x10000>;
					interrupts = <0x00 0x1f 0x04>;
					clocks = <0x02 0x9f 0x02 0x9f>;
					clock-names = "ipg", "per";
					dmas = <0x26 0x00 0x07 0x01 0x26 0x01 0x07 0x02>;
					dma-names = "rx", "tx";
					status = "disabled";
				};

				spi@30830000 {
					compatible = "fsl,imx8mm-ecspi", "fsl,imx51-ecspi";
					#address-cells = <0x01>;
					#size-cells = <0x00>;
					reg = <0x30830000 0x10000>;
					interrupts = <0x00 0x20 0x04>;
					clocks = <0x02 0xa0 0x02 0xa0>;
					clock-names = "ipg", "per";
					dmas = <0x26 0x02 0x07 0x01 0x26 0x03 0x07 0x02>;
					dma-names = "rx", "tx";
					status = "okay";
					fsl,spi-num-chipselects = <0x01>;
					pinctrl-names = "default";
					pinctrl-0 = <0x27 0x28>;
					cs-gpios = <0x29 0x0d 0x01>;

					spi@0 {
						reg = <0x00>;
						compatible = "rohm,dh2228fv";
						spi-max-frequency = <0x7a120>;
					};
				};

				spi@30840000 {
					compatible = "fsl,imx8mm-ecspi", "fsl,imx51-ecspi";
					#address-cells = <0x01>;
					#size-cells = <0x00>;
					reg = <0x30840000 0x10000>;
					interrupts = <0x00 0x21 0x04>;
					clocks = <0x02 0xa1 0x02 0xa1>;
					clock-names = "ipg", "per";
					dmas = <0x26 0x04 0x07 0x01 0x26 0x05 0x07 0x02>;
					dma-names = "rx", "tx";
					status = "disabled";
				};

				serial@30860000 {
					compatible = "fsl,imx8mm-uart", "fsl,imx6q-uart";
					reg = <0x30860000 0x10000>;
					interrupts = <0x00 0x1a 0x04>;
					clocks = <0x02 0xbc 0x02 0xbc>;
					clock-names = "ipg", "per";
					dmas = <0x26 0x16 0x04 0x00 0x26 0x17 0x04 0x00>;
					dma-names = "rx", "tx";
					status = "okay";
					pinctrl-names = "default";
					pinctrl-0 = <0x2a>;
					assigned-clocks = <0x02 0x7f>;
					assigned-clock-parents = <0x02 0x31>;
					fsl,uart-has-rtscts;

					bluetooth {
						compatible = "nxp,88w8987-bt";
					};
				};

				serial@30880000 {
					compatible = "fsl,imx8mm-uart", "fsl,imx6q-uart";
					reg = <0x30880000 0x10000>;
					interrupts = <0x00 0x1c 0x04>;
					clocks = <0x02 0xbe 0x02 0xbe>;
					clock-names = "ipg", "per";
					dmas = <0x26 0x1a 0x04 0x00 0x26 0x1b 0x04 0x00>;
					dma-names = "rx", "tx";
					status = "okay";
					pinctrl-names = "default";
					pinctrl-0 = <0x2b>;
					assigned-clocks = <0x02 0x81>;
					assigned-clock-parents = <0x02 0x31>;
					fsl,uart-has-rtscts;
				};

				serial@30890000 {
					compatible = "fsl,imx8mm-uart", "fsl,imx6q-uart";
					reg = <0x30890000 0x10000>;
					interrupts = <0x00 0x1b 0x04>;
					clocks = <0x02 0xbd 0x02 0xbd>;
					clock-names = "ipg", "per";
					status = "okay";
					pinctrl-names = "default";
					pinctrl-0 = <0x2c>;
				};
			};

			crypto@30900000 {
				compatible = "fsl,sec-v4.0";
				#address-cells = <0x01>;
				#size-cells = <0x01>;
				reg = <0x30900000 0x40000>;
				ranges = <0x00 0x30900000 0x40000>;
				interrupts = <0x00 0x5b 0x04>;
				clocks = <0x02 0x5d 0x02 0x5f>;
				clock-names = "aclk", "ipg";

				jr@1000 {
					compatible = "fsl,sec-v4.0-job-ring";
					reg = <0x1000 0x1000>;
					interrupts = <0x00 0x69 0x04>;
					status = "disabled";
				};

				jr@2000 {
					compatible = "fsl,sec-v4.0-job-ring";
					reg = <0x2000 0x1000>;
					interrupts = <0x00 0x6a 0x04>;
				};

				jr@3000 {
					compatible = "fsl,sec-v4.0-job-ring";
					reg = <0x3000 0x1000>;
					interrupts = <0x00 0x72 0x04>;
				};
			};

			i2c@30a20000 {
				compatible = "fsl,imx8mm-i2c", "fsl,imx21-i2c";
				#address-cells = <0x01>;
				#size-cells = <0x00>;
				reg = <0x30a20000 0x10000>;
				interrupts = <0x00 0x23 0x04>;
				clocks = <0x02 0xa4>;
				status = "okay";
				clock-frequency = <0x61a80>;
				pinctrl-names = "default";
				pinctrl-0 = <0x2d>;

				pca9450@25 {
					compatible = "nxp,pca9450a";
					reg = <0x25>;
					pinctrl-0 = <0x2e>;
					pinctrl-names = "default";
					interrupt-parent = <0x2f>;
					interrupts = <0x03 0x08>;

					regulators {

						BUCK1 {
							regulator-name = "BUCK1";
							regulator-min-microvolt = <0x927c0>;
							regulator-max-microvolt = <0x2160ec>;
							regulator-boot-on;
							regulator-always-on;
							regulator-ramp-delay = <0xc35>;
							nxp,dvs-run-voltage = <0xcf850>;
							nxp,dvs-standby-voltage = "", "\f5";
						};

						BUCK2 {
							regulator-name = "BUCK2";
							regulator-min-microvolt = <0x927c0>;
							regulator-max-microvolt = <0x2160ec>;
							regulator-boot-on;
							regulator-always-on;
							regulator-ramp-delay = <0xc35>;
							phandle = <0x07>;
						};

						BUCK3 {
							regulator-name = "BUCK3";
							regulator-min-microvolt = <0x927c0>;
							regulator-max-microvolt = <0x2160ec>;
							regulator-boot-on;
							regulator-always-on;
						};

						BUCK4 {
							regulator-name = "BUCK4";
							regulator-min-microvolt = <0x927c0>;
							regulator-max-microvolt = <0x33e140>;
							regulator-boot-on;
							regulator-always-on;
							phandle = <0x37>;
						};

						BUCK5 {
							regulator-name = "BUCK5";
							regulator-min-microvolt = <0x927c0>;
							regulator-max-microvolt = <0x33e140>;
							regulator-boot-on;
							regulator-always-on;
						};

						BUCK6 {
							regulator-name = "BUCK6";
							regulator-min-microvolt = <0x927c0>;
							regulator-max-microvolt = <0x33e140>;
							regulator-boot-on;
							regulator-always-on;
						};

						LDO1 {
							regulator-name = "LDO1";
							regulator-min-microvolt = <0x186a00>;
							regulator-max-microvolt = <0x325aa0>;
							regulator-boot-on;
							regulator-always-on;
						};

						LDO2 {
							regulator-name = "LDO2";
							regulator-min-microvolt = "", "\f5";
							regulator-max-microvolt = <0x118c30>;
							regulator-boot-on;
							regulator-always-on;
						};

						LDO3 {
							regulator-name = "LDO3";
							regulator-min-microvolt = "", "\f5";
							regulator-max-microvolt = <0x325aa0>;
							regulator-boot-on;
							regulator-always-on;
						};

						LDO4 {
							regulator-name = "LDO4";
							regulator-min-microvolt = "", "\f5";
							regulator-max-microvolt = <0x325aa0>;
							regulator-boot-on;
							regulator-always-on;
						};

						LDO5 {
							regulator-name = "LDO5";
							regulator-min-microvolt = <0x1b7740>;
							regulator-max-microvolt = <0x325aa0>;
						};
					};
				};
			};

			i2c@30a30000 {
				compatible = "fsl,imx8mm-i2c", "fsl,imx21-i2c";
				#address-cells = <0x01>;
				#size-cells = <0x00>;
				reg = <0x30a30000 0x10000>;
				interrupts = <0x00 0x24 0x04>;
				clocks = <0x02 0xa5>;
				status = "okay";
				clock-frequency = <0x61a80>;
				pinctrl-names = "default";
				pinctrl-0 = <0x30>;

				adv7535@3d {
					compatible = "adi,adv7535";
					reg = <0x3d>;
					adi,addr-cec = <0x3b>;
					adi,dsi-lanes = <0x04>;
					pinctrl-names = "default";
					pinctrl-0 = <0x31>;
					interrupt-parent = <0x2f>;
					interrupts = <0x09 0x08>;
					status = "okay";

					port {

						endpoint {
							remote-endpoint = <0x32>;
							phandle = <0x54>;
						};
					};
				};

				tcpc@50 {
					compatible = "nxp,ptn5110";
					pinctrl-names = "default";
					pinctrl-0 = <0x33>;
					reg = <0x50>;
					interrupt-parent = <0x34>;
					interrupts = <0x0b 0x08>;
					status = "okay";

					port {

						endpoint {
							remote-endpoint = <0x35>;
							phandle = <0x5d>;
						};
					};

					connector {
						compatible = "usb-c-connector";
						label = "USB-C";
						power-role = "dual";
						data-role = "dual";
						try-power-role = "sink";
						source-pdos = <0x401912c>;
						sink-pdos = <0x401912c 0x9901912c>;
						op-sink-microwatt = <0xe4e1c0>;
						self-powered;
					};
				};
			};

			i2c@30a40000 {
				#address-cells = <0x01>;
				#size-cells = <0x00>;
				compatible = "fsl,imx8mm-i2c", "fsl,imx21-i2c";
				reg = <0x30a40000 0x10000>;
				interrupts = <0x00 0x25 0x04>;
				clocks = <0x02 0xa6>;
				status = "okay";
				clock-frequency = <0x186a0>;
				pinctrl-names = "default";
				pinctrl-0 = <0x36>;

				gpio@20 {
					compatible = "ti,tca6416";
					reg = <0x20>;
					gpio-controller;
					#gpio-cells = <0x02>;
					vcc-supply = <0x37>;
					phandle = <0x39>;
				};

				ak4458@10 {
					#sound-dai-cells = <0x00>;
					sound-name-prefix = "0";
					compatible = "asahi-kasei,ak4458";
					reg = <0x10>;
					AVDD-supply = <0x38>;
					DVDD-supply = <0x38>;
					phandle = <0x7a>;
				};

				ak4458@12 {
					#sound-dai-cells = <0x00>;
					sound-name-prefix = "1";
					compatible = "asahi-kasei,ak4458";
					reg = <0x12>;
					AVDD-supply = <0x38>;
					DVDD-supply = <0x38>;
					phandle = <0x7b>;
				};

				ak5558@13 {
					#sound-dai-cells = <0x00>;
					compatible = "asahi-kasei,ak5558";
					reg = <0x13>;
					reset-gpios = <0x39 0x03 0x01>;
					AVDD-supply = <0x38>;
					DVDD-supply = <0x38>;
					phandle = <0x7d>;
				};

				ak4497@11 {
					#sound-dai-cells = <0x00>;
					compatible = "asahi-kasei,ak4497";
					reg = <0x11>;
					reset-gpios = <0x39 0x05 0x01>;
					AVDD-supply = <0x38>;
					DVDD-supply = <0x38>;
					dsd-path = <0x01>;
					phandle = <0x7e>;
				};

				ov5640_mipi@3c {
					compatible = "ovti,ov5640_mipi";
					reg = <0x3c>;
					status = "okay";
					pinctrl-names = "default";
					pinctrl-0 = <0x3a 0x3b>;
					clocks = <0x02 0x9e>;
					clock-names = "csi_mclk";
					assigned-clocks = <0x02 0x9e>;
					assigned-clock-parents = <0x02 0x02>;
					assigned-clock-rates = <0x16e3600>;
					csi_id = <0x00>;
					pwn-gpios = <0x2f 0x07 0x00>;
					mclk = <0x16e3600>;
					mclk_source = <0x00>;

					port {

						endpoint {
							remote-endpoint = <0x3c>;
							phandle = <0x56>;
						};
					};
				};
			};

			i2c@30a50000 {
				compatible = "fsl,imx8mm-i2c", "fsl,imx21-i2c";
				#address-cells = <0x01>;
				#size-cells = <0x00>;
				reg = <0x30a50000 0x10000>;
				interrupts = <0x00 0x26 0x04>;
				clocks = <0x02 0xa7>;
				status = "disabled";
			};

			serial@30a60000 {
				compatible = "fsl,imx8mm-uart", "fsl,imx6q-uart";
				reg = <0x30a60000 0x10000>;
				interrupts = <0x00 0x1d 0x04>;
				clocks = <0x02 0xbf 0x02 0xbf>;
				clock-names = "ipg", "per";
				dmas = <0x26 0x1c 0x04 0x00 0x26 0x1d 0x04 0x00>;
				dma-names = "rx", "tx";
				status = "disabled";
			};

			mailbox@30aa0000 {
				compatible = "fsl,imx8mm-mu", "fsl,imx6sx-mu";
				reg = <0x30aa0000 0x10000>;
				interrupts = <0x00 0x58 0x04>;
				clocks = <0x02 0xda>;
				#mbox-cells = <0x02>;
			};

			mmc@30b40000 {
				compatible = "fsl,imx8mm-usdhc", "fsl,imx7d-usdhc";
				reg = <0x30b40000 0x10000>;
				interrupts = <0x00 0x16 0x04>;
				clocks = <0x02 0x5f 0x02 0x53 0x02 0xc2>;
				clock-names = "ipg", "ahb", "per";
				fsl,tuning-start-tap = <0x14>;
				fsl,tuning-step = <0x02>;
				bus-width = <0x04>;
				status = "okay";
				pinctrl-names = "default", "state_100mhz", "state_200mhz";
				pinctrl-0 = <0x3d 0x3e>;
				pinctrl-1 = <0x3f 0x3e>;
				pinctrl-2 = <0x40 0x3e>;
				keep-power-in-suspend;
				non-removable;
				wakeup-source;
				vmmc-supply = <0x41>;
				fsl,sdio-async-interrupt-enabled;

				wifi_wake_host {
					compatible = "nxp,wifi-wake-host";
					interrupt-parent = <0x34>;
					interrupts = <0x09 0x08>;
					interrupt-names = "host-wake";
				};
			};

			mmc@30b50000 {
				compatible = "fsl,imx8mm-usdhc", "fsl,imx7d-usdhc";
				reg = <0x30b50000 0x10000>;
				interrupts = <0x00 0x17 0x04>;
				clocks = <0x02 0x5f 0x02 0x53 0x02 0xc3>;
				clock-names = "ipg", "ahb", "per";
				fsl,tuning-start-tap = <0x14>;
				fsl,tuning-step = <0x02>;
				bus-width = <0x04>;
				status = "okay";
				assigned-clocks = <0x02 0x7a>;
				assigned-clock-rates = <0xbebc200>;
				pinctrl-names = "default", "state_100mhz", "state_200mhz";
				pinctrl-0 = <0x42 0x43>;
				pinctrl-1 = <0x44 0x43>;
				pinctrl-2 = <0x45 0x43>;
				cd-gpios = <0x2f 0x0f 0x01>;
				vmmc-supply = <0x46>;
			};

			mmc@30b60000 {
				compatible = "fsl,imx8mm-usdhc", "fsl,imx7d-usdhc";
				reg = <0x30b60000 0x10000>;
				interrupts = <0x00 0x18 0x04>;
				clocks = <0x02 0x5f 0x02 0x53 0x02 0xd0>;
				clock-names = "ipg", "ahb", "per";
				fsl,tuning-start-tap = <0x14>;
				fsl,tuning-step = <0x02>;
				bus-width = <0x08>;
				status = "okay";
				assigned-clocks = <0x02 0xd0>;
				assigned-clock-rates = <0x17d78400>;
				pinctrl-names = "default", "state_100mhz", "state_200mhz";
				pinctrl-0 = <0x47>;
				pinctrl-1 = <0x48>;
				pinctrl-2 = <0x49>;
				non-removable;
			};

			spi@30bb0000 {
				#address-cells = <0x01>;
				#size-cells = <0x00>;
				compatible = "nxp,imx8mm-fspi";
				reg = <0x30bb0000 0x10000 0x8000000 0x10000000>;
				reg-names = "fspi_base", "fspi_mmap";
				interrupts = <0x00 0x6b 0x04>;
				clocks = <0x02 0xae 0x02 0xae>;
				clock-names = "fspi_en", "fspi";
				status = "okay";
				pinctrl-names = "default";
				pinctrl-0 = <0x4a>;

				flash@0 {
					reg = <0x00>;
					#address-cells = <0x01>;
					#size-cells = <0x01>;
					compatible = "jedec,spi-nor";
					spi-max-frequency = <0x4c4b400>;
					spi-tx-bus-width = <0x01>;
					spi-rx-bus-width = <0x04>;
				};
			};

			dma-controller@30bd0000 {
				compatible = "fsl,imx8mm-sdma", "fsl,imx8mq-sdma";
				reg = <0x30bd0000 0x10000>;
				interrupts = <0x00 0x02 0x04>;
				clocks = <0x02 0xd3 0x02 0x5d>;
				clock-names = "ipg", "ahb";
				#dma-cells = <0x03>;
				fsl,sdma-ram-script-name = "imx/sdma/sdma-imx7d.bin";
				phandle = <0x26>;
			};

			ethernet@30be0000 {
				compatible = "fsl,imx8mm-fec", "fsl,imx8mq-fec", "fsl,imx6sx-fec";
				reg = <0x30be0000 0x10000>;
				interrupts = <0x00 0x76 0x04 0x00 0x77 0x04 0x00 0x78 0x04 0x00 0x79 0x04>;
				clocks = <0x02 0xa2 0x02 0xa2 0x02 0x75 0x02 0x74 0x02 0x76>;
				clock-names = "ipg", "ahb", "ptp", "enet_clk_ref", "enet_out";
				assigned-clocks = <0x02 0x52 0x02 0x75 0x02 0x74 0x02 0x76>;
				assigned-clock-parents = <0x02 0x36 0x02 0x3a 0x02 0x3b 0x02 0x39>;
				assigned-clock-rates = <0x00 0x5f5e100 0x7735940 0x00>;
				fsl,num-tx-queues = <0x03>;
				fsl,num-rx-queues = <0x03>;
				nvmem-cells = <0x4b>;
				nvmem-cell-names = "mac-address";
				fsl,stop-mode = <0x4c 0x10 0x03>;
				status = "okay";
				pinctrl-names = "default";
				pinctrl-0 = <0x4d>;
				phy-mode = "rgmii-id";
				phy-handle = <0x4e>;
				fsl,magic-packet;

				mdio {
					#address-cells = <0x01>;
					#size-cells = <0x00>;

					ethernet-phy@0 {
						compatible = "ethernet-phy-ieee802.3-c22";
						reg = <0x00>;
						reset-gpios = <0x4f 0x16 0x01>;
						reset-assert-us = <0x2710>;
						reset-deassert-us = <0x13880>;
						realtek,aldps-enable;
						realtek,clkout-disable;
						qca,disable-smarteee;
						vddio-supply = <0x50>;
						phandle = <0x4e>;

						vddio-regulator {
							regulator-min-microvolt = <0x1b7740>;
							regulator-max-microvolt = <0x1b7740>;
							phandle = <0x50>;
						};
					};
				};
			};
		};

		bus@32c00000 {
			compatible = "fsl,aips-bus", "simple-bus";
			reg = <0x32c00000 0x400000>;
			#address-cells = <0x01>;
			#size-cells = <0x01>;
			ranges = <0x32c00000 0x32c00000 0x400000>;

			lcdif@32e00000 {
				#address-cells = <0x01>;
				#size-cells = <0x00>;
				compatible = "fsl,imx8mm-lcdif";
				reg = <0x32e00000 0x10000>;
				clocks = <0x02 0x6b 0x02 0xcd 0x02 0xce>;
				clock-names = "pix", "disp-axi", "disp-apb";
				assigned-clocks = <0x02 0x6b 0x02 0x55 0x02 0x56>;
				assigned-clock-parents = <0x02 0x28 0x02 0x41 0x02 0x38>;
				assigned-clock-rate = <0x2367b880 0x1dcd6500 0xbebc200>;
				interrupts = <0x00 0x05 0x04>;
				power-domains = <0x51 0x01>;
				status = "okay";

				port@0 {
					reg = <0x00>;
					phandle = <0x5a>;

					endpoint {
						remote-endpoint = <0x52>;
						phandle = <0x53>;
					};
				};
			};

			mipi_dsi@32e10000 {
				#address-cells = <0x01>;
				#size-cells = <0x00>;
				compatible = "fsl,imx8mm-mipi-dsim";
				reg = <0x32e10000 0x400>;
				clocks = <0x02 0x8e 0x02 0x8f 0x02 0xce>;
				clock-names = "cfg", "pll-ref", "apb-root";
				assigned-clocks = <0x02 0x8e 0x02 0x8f>;
				assigned-clock-parents = <0x02 0x36 0x02 0x02>;
				assigned-clock-rates = <0xfdad680 0xb71b00>;
				interrupts = <0x00 0x12 0x04>;
				power-domains = <0x51 0x02>;
				status = "okay";

				port@0 {

					endpoint {
						remote-endpoint = <0x53>;
						phandle = <0x52>;
					};
				};

				port@1 {

					endpoint {
						remote-endpoint = <0x54>;
						attach-bridge;
						phandle = <0x32>;
					};
				};
			};

			csi1_bridge@32e20000 {
				compatible = "fsl,imx8mm-csi", "fsl,imx8mq-csi", "fsl,imx6s-csi";
				reg = <0x32e20000 0x1000>;
				interrupts = <0x00 0x10 0x04>;
				clocks = <0x02 0xcd 0x02 0xdb 0x02 0xce>;
				clock-names = "disp-axi", "csi_mclk", "disp_dcic";
				power-domains = <0x51 0x00>;
				status = "okay";
				fsl,mipi-mode;

				port {

					endpoint {
						remote-endpoint = <0x55>;
						phandle = <0x57>;
					};
				};
			};

			mipi_csi@32e30000 {
				compatible = "fsl,imx8mm-mipi-csi";
				reg = <0x32e30000 0x1000>;
				interrupts = <0x00 0x11 0x04>;
				clock-frequency = <0x13d92d40>;
				clocks = <0x02 0x92 0x02 0x93 0x02 0xcd 0x02 0xce>;
				clock-names = "mipi_clk", "phy_clk", "disp_axi", "disp_apb";
				bus-width = <0x04>;
				power-domains = <0x51 0x03>;
				status = "okay";
				#address-cells = <0x01>;
				#size-cells = <0x00>;

				port {

					endpoint@1 {
						remote-endpoint = <0x56>;
						data-lanes = <0x02>;
						csis-hs-settle = <0x0d>;
						csis-clk-settle = <0x02>;
						csis-wclk;
						phandle = <0x3c>;
					};

					endpoint@2 {
						remote-endpoint = <0x57>;
						phandle = <0x55>;
					};
				};
			};

			blk-ctrl@32e28000 {
				compatible = "fsl,imx8mm-disp-blk-ctrl", "syscon";
				reg = <0x32e28000 0x100>;
				power-domains = <0x58 0x58 0x58 0x59 0x59>;
				power-domain-names = "bus", "csi-bridge", "lcdif", "mipi-dsi", "mipi-csi";
				clocks = <0x02 0xcd 0x02 0xce 0x02 0xdb 0x02 0xcd 0x02 0xce 0x02 0xcc 0x02 0x8e 0x02 0x8f 0x02 0x92 0x02 0x93>;
				clock-names = "csi-bridge-axi", "csi-bridge-apb", "csi-bridge-core", "lcdif-axi", "lcdif-apb", "lcdif-pix", "dsi-pclk", "dsi-ref", "csi-aclk", "csi-pclk";
				#power-domain-cells = <0x01>;
				phandle = <0x51>;
			};

			display-subsystem {
				compatible = "fsl,imx-display-subsystem";
				ports = <0x5a>;
			};

			usb@32e40000 {
				compatible = "fsl,imx8mm-usb", "fsl,imx7d-usb";
				reg = <0x32e40000 0x200>;
				interrupts = <0x00 0x28 0x04>;
				clocks = <0x02 0xc0>;
				clock-names = "usb1_ctrl_root_clk";
				assigned-clocks = <0x02 0x58>;
				assigned-clock-parents = <0x02 0x40>;
				phys = <0x5b>;
				fsl,usbmisc = <0x5c 0x00>;
				power-domains = <0x22>;
				status = "okay";
				dr_mode = "otg";
				hnp-disable;
				srp-disable;
				adp-disable;
				usb-role-switch;
				disable-over-current;
				samsung,picophy-pre-emp-curr-control = <0x03>;
				samsung,picophy-dc-vol-level-adjust = <0x07>;

				port {

					endpoint {
						remote-endpoint = <0x5d>;
						phandle = <0x35>;
					};
				};
			};

			usbmisc@32e40200 {
				compatible = "fsl,imx8mm-usbmisc", "fsl,imx7d-usbmisc";
				#index-cells = <0x01>;
				reg = <0x32e40200 0x200>;
				phandle = <0x5c>;
			};

			usb@32e50000 {
				compatible = "fsl,imx8mm-usb", "fsl,imx7d-usb";
				reg = <0x32e50000 0x200>;
				interrupts = <0x00 0x29 0x04>;
				clocks = <0x02 0xc0>;
				clock-names = "usb1_ctrl_root_clk";
				assigned-clocks = <0x02 0x58>;
				assigned-clock-parents = <0x02 0x40>;
				phys = <0x5e>;
				fsl,usbmisc = <0x5f 0x00>;
				power-domains = <0x22>;
				status = "disabled";
			};

			usbmisc@32e50200 {
				compatible = "fsl,imx8mm-usbmisc", "fsl,imx7d-usbmisc";
				#index-cells = <0x01>;
				reg = <0x32e50200 0x200>;
				phandle = <0x5f>;
			};

			pcie-phy@32f00000 {
				compatible = "fsl,imx8mm-pcie-phy";
				reg = <0x32f00000 0x10000>;
				clocks = <0x60>;
				clock-names = "ref";
				assigned-clocks = <0x02 0x68>;
				assigned-clock-rates = <0x5f5e100>;
				assigned-clock-parents = <0x02 0x3a>;
				resets = <0x23 0x1a>;
				reset-names = "pciephy";
				#phy-cells = <0x00>;
				status = "okay";
				fsl,refclk-pad-mode = <0x01>;
				fsl,tx-deemph-gen1 = <0x2d>;
				fsl,tx-deemph-gen2 = <0x0f>;
				phandle = <0x63>;
			};
		};

		dma-controller@33000000 {
			compatible = "fsl,imx7d-dma-apbh", "fsl,imx28-dma-apbh";
			reg = <0x33000000 0x2000>;
			interrupts = <0x00 0x0c 0x04 0x00 0x0c 0x04 0x00 0x0c 0x04 0x00 0x0c 0x04>;
			interrupt-names = "gpmi0", "gpmi1", "gpmi2", "gpmi3";
			#dma-cells = <0x01>;
			dma-channels = <0x04>;
			clocks = <0x02 0xde>;
			phandle = <0x61>;
		};

		nand-controller@33002000 {
			compatible = "fsl,imx8mm-gpmi-nand", "fsl,imx7d-gpmi-nand";
			#address-cells = <0x01>;
			#size-cells = <0x00>;
			reg = <0x33002000 0x2000 0x33004000 0x4000>;
			reg-names = "gpmi-nand", "bch";
			interrupts = <0x00 0x0e 0x04>;
			interrupt-names = "bch";
			clocks = <0x02 0xaf 0x02 0xde>;
			clock-names = "gpmi_io", "gpmi_bch_apb";
			dmas = <0x61 0x00>;
			dma-names = "rx-tx";
			status = "disabled";
		};

		pcie@33800000 {
			compatible = "fsl,imx8mm-pcie";
			reg = <0x33800000 0x400000 0x1ff00000 0x80000>;
			reg-names = "dbi", "config";
			#address-cells = <0x03>;
			#size-cells = <0x02>;
			device_type = "pci";
			bus-range = <0x00 0xff>;
			ranges = <0x81000000 0x00 0x00 0x1ff80000 0x00 0x10000 0x82000000 0x00 0x18000000 0x18000000 0x00 0x7f00000>;
			num-lanes = <0x01>;
			num-viewport = <0x04>;
			interrupts = <0x00 0x7a 0x04>;
			interrupt-names = "msi";
			#interrupt-cells = <0x01>;
			interrupt-map-mask = <0x00 0x00 0x00 0x07>;
			interrupt-map = <0x00 0x00 0x00 0x01 0x01 0x00 0x7d 0x04 0x00 0x00 0x00 0x02 0x01 0x00 0x7c 0x04 0x00 0x00 0x00 0x03 0x01 0x00 0x7b 0x04 0x00 0x00 0x00 0x04 0x01 0x00 0x7a 0x04>;
			fsl,max-link-speed = <0x02>;
			linux,pci-domain = <0x00>;
			power-domains = <0x62>;
			resets = <0x23 0x1c 0x23 0x1d>;
			reset-names = "apps", "turnoff";
			phys = <0x63>;
			phy-names = "pcie-phy";
			status = "okay";
			pinctrl-names = "default";
			pinctrl-0 = <0x64>;
			reset-gpio = <0x4f 0x15 0x01>;
			clocks = <0x02 0xa9 0x02 0x69 0x60>;
			clock-names = "pcie", "pcie_aux", "pcie_bus";
			assigned-clocks = <0x02 0x69 0x02 0x67>;
			assigned-clock-rates = <0x989680 0xee6b280>;
			assigned-clock-parents = <0x02 0x39 0x02 0x3e>;
			vpcie-supply = <0x65>;
		};

		pcie_ep@33800000 {
			compatible = "fsl,imx8mm-pcie-ep";
			reg = <0x33800000 0x400000 0x18000000 0x8000000>;
			reg-names = "regs", "addr_space";
			num-lanes = <0x01>;
			interrupts = <0x00 0x7f 0x04>;
			interrupt-names = "dma";
			fsl,max-link-speed = <0x02>;
			power-domains = <0x62>;
			resets = <0x23 0x1c 0x23 0x1d>;
			reset-names = "apps", "turnoff";
			phys = <0x63>;
			phy-names = "pcie-phy";
			num-ib-windows = <0x04>;
			num-ob-windows = <0x04>;
			status = "disabled";
			pinctrl-names = "default";
			pinctrl-0 = <0x64>;
			clocks = <0x02 0xa9 0x02 0x69 0x02 0x68 0x60>;
			clock-names = "pcie", "pcie_aux", "pcie_phy", "pcie_bus";
			ext_osc = <0x01>;
		};

		blk-ctrl@38330000 {
			compatible = "fsl,imx8mm-vpu-blk-ctrl", "syscon";
			reg = <0x38330000 0x100>;
			power-domains = <0x66 0x67 0x68 0x69>;
			power-domain-names = "bus", "g1", "g2", "h1";
			clocks = <0x02 0xc7 0x02 0xca 0x02 0xc9>;
			clock-names = "g1", "g2", "h1";
			assigned-clocks = <0x02 0x63 0x02 0x64>;
			assigned-clock-parents = <0x02 0x2b 0x02 0x2b>;
			assigned-clock-rates = <0x23c34600 0x23c34600>;
			#power-domain-cells = <0x01>;
			phandle = <0x6a>;
		};

		interrupt-controller@38800000 {
			compatible = "arm,gic-v3";
			reg = <0x38800000 0x10000 0x38880000 0xc0000>;
			#interrupt-cells = <0x03>;
			interrupt-controller;
			interrupts = <0x01 0x09 0x04>;
			phandle = <0x01>;
		};

		ddr-pmu@3d800000 {
			compatible = "fsl,imx8mm-ddr-pmu", "fsl,imx8m-ddr-pmu";
			reg = <0x3d800000 0x400000>;
			interrupts = <0x00 0x62 0x04>;
		};
	};

	vpu_h1@38320000 {
		compatible = "nxp,imx8mm-hantro-h1";
		reg = <0x00 0x38320000 0x00 0x10000>;
		reg-names = "regs_hantro_h1";
		interrupts = <0x00 0x1e 0x04>;
		interrupt-names = "irq_hantro_h1";
		clocks = <0x02 0xc9 0x02 0xd2>;
		clock-names = "clk_hantro_h1", "clk_hantro_h1_bus";
		assigned-clocks = <0x02 0x9d 0x02 0x54>;
		assigned-clock-parents = <0x02 0x2b 0x02 0x38>;
		assigned-clock-rates = <0x23c34600 0x2faf0800>;
		power-domains = <0x6a 0x02>;
		status = "okay";
	};

	vpu_g1@38300000 {
		compatible = "nxp,imx8mm-hantro";
		reg = <0x00 0x38300000 0x00 0x100000>;
		reg-names = "regs_hantro";
		interrupts = <0x00 0x07 0x04>;
		interrupt-names = "irq_hantro";
		clocks = <0x02 0xc7 0x02 0xd2>;
		clock-names = "clk_hantro", "clk_hantro_bus";
		assigned-clocks = <0x02 0x63 0x02 0x54>;
		assigned-clock-parents = <0x02 0x2b 0x02 0x38>;
		assigned-clock-rates = <0x23c34600 0x2faf0800>;
		power-domains = <0x6a 0x00>;
		status = "okay";
	};

	vpu_g2@38310000 {
		compatible = "nxp,imx8mm-hantro";
		reg = <0x00 0x38310000 0x00 0x100000>;
		reg-names = "regs_hantro";
		interrupts = <0x00 0x08 0x04>;
		interrupt-names = "irq_hantro";
		clocks = <0x02 0xca 0x02 0xd2>;
		clock-names = "clk_hantro", "clk_hantro_bus";
		assigned-clocks = <0x02 0x64 0x02 0x54>;
		assigned-clock-parents = <0x02 0x2b 0x02 0x38>;
		assigned-clock-rates = <0x23c34600 0x2faf0800>;
		power-domains = <0x6a 0x01>;
		status = "okay";
	};

	vpu_v4l2 {
		compatible = "nxp,imx8m-vsiv4l2";
		status = "okay";
	};

	gpu@38000000 {
		compatible = "fsl,imx8mm-gpu", "fsl,imx6q-gpu";
		reg = <0x00 0x38000000 0x00 0x8000 0x00 0x38008000 0x00 0x8000 0x00 0x40000000 0x00 0x80000000 0x00 0x00 0x00 0x8000000>;
		reg-names = "iobase_3d", "iobase_2d", "phys_baseaddr", "contiguous_mem";
		interrupts = <0x00 0x03 0x04 0x00 0x19 0x04>;
		interrupt-names = "irq_3d", "irq_2d";
		clocks = <0x02 0xc1 0x02 0x00 0x02 0xc8 0x02 0x5a 0x02 0xd9 0x02 0xc8 0x02 0x5a>;
		clock-names = "gpu3d_clk", "gpu3d_shader_clk", "gpu3d_axi_clk", "gpu3d_ahb_clk", "gpu2d_clk", "gpu2d_axi_clk", "gpu2d_ahb_clk";
		assigned-clocks = <0x02 0x45 0x02 0x46 0x02 0x59 0x02 0x5a 0x02 0x2a>;
		assigned-clock-parents = <0x02 0x2a 0x02 0x2a 0x02 0x38 0x02 0x38>;
		assigned-clock-rates = <0x00 0x00 0x00 0x17d78400 0x3b9aca00>;
		power-domains = <0x6b>;
		status = "okay";
	};

	chosen {
		stdout-path = "/soc@0/bus@30800000/spba-bus@30800000/serial@30890000";
	};

	memory@40000000 {
		device_type = "memory";
		reg = <0x00 0x40000000 0x00 0x80000000>;
	};

	ir-receiver {
		compatible = "gpio-ir-receiver";
		gpios = <0x2f 0x0d 0x01>;
		pinctrl-names = "default";
		pinctrl-0 = <0x6c>;
		linux,autosuspend-period = <0x7d>;
	};

	leds {
		compatible = "gpio-leds";
		pinctrl-names = "default";
		pinctrl-0 = <0x6d>;

		status {
			label = "status";
			gpios = <0x6e 0x10 0x00>;
			default-state = "on";
		};
	};

	pcie0-refclk {
		compatible = "fixed-clock";
		#clock-cells = <0x00>;
		clock-frequency = <0x5f5e100>;
		phandle = <0x60>;
	};

	regulator-audio-board {
		compatible = "regulator-fixed";
		regulator-name = "EXT_PWREN";
		regulator-min-microvolt = <0x325aa0>;
		regulator-max-microvolt = <0x325aa0>;
		enable-active-high;
		startup-delay-us = <0x493e0>;
		gpio = <0x39 0x01 0x00>;
		regulator-always-on;
		phandle = <0x38>;
	};

	regulator-pcie {
		compatible = "regulator-fixed";
		pinctrl-names = "default";
		pinctrl-0 = <0x6f>;
		regulator-name = "MPCIE_3V3";
		regulator-min-microvolt = <0x325aa0>;
		regulator-max-microvolt = <0x325aa0>;
		gpio = <0x2f 0x05 0x00>;
		enable-active-high;
		phandle = <0x65>;
	};

	regulator-usdhc2 {
		compatible = "regulator-fixed";
		pinctrl-names = "default";
		pinctrl-0 = <0x70>;
		regulator-name = "VSD_3V3";
		regulator-min-microvolt = <0x325aa0>;
		regulator-max-microvolt = <0x325aa0>;
		gpio = <0x34 0x13 0x00>;
		off-on-delay-us = <0x4e20>;
		enable-active-high;
		phandle = <0x46>;
	};

	backlight {
		compatible = "pwm-backlight";
		pwms = <0x71 0x00 0x4c4b40 0x00>;
		brightness-levels = <0x00 0xff>;
		num-interpolated-steps = <0xff>;
		default-brightness-level = <0xfa>;
	};

	audio-codec-bt-sco {
		compatible = "linux,bt-sco";
		#sound-dai-cells = <0x01>;
		phandle = <0x75>;
	};

	audio-codec {
		#sound-dai-cells = <0x00>;
		compatible = "wlf,wm8524";
		pinctrl-names = "default";
		pinctrl-0 = <0x72>;
		wlf,mute-gpios = <0x29 0x15 0x01>;
		phandle = <0x78>;
	};

	sound-bt-sco {
		compatible = "simple-audio-card";
		simple-audio-card,name = "bt-sco-audio";
		simple-audio-card,format = "dsp_a";
		simple-audio-card,bitclock-inversion;
		simple-audio-card,frame-master = <0x73>;
		simple-audio-card,bitclock-master = <0x73>;

		simple-audio-card,cpu {
			sound-dai = <0x74>;
			dai-tdm-slot-num = <0x02>;
			dai-tdm-slot-width = <0x10>;
			phandle = <0x73>;
		};

		simple-audio-card,codec {
			sound-dai = <0x75 0x01>;
		};
	};

	sound-wm8524 {
		compatible = "simple-audio-card";
		simple-audio-card,name = "wm8524-audio";
		simple-audio-card,format = "i2s";
		simple-audio-card,frame-master = <0x76>;
		simple-audio-card,bitclock-master = <0x76>;
		simple-audio-card,widgets = "Line", "Left Line Out Jack", "Line", "Right Line Out Jack";
		simple-audio-card,routing = "Left Line Out Jack", "LINEVOUTL", "Right Line Out Jack", "LINEVOUTR";

		simple-audio-card,cpu {
			sound-dai = <0x77>;
			dai-tdm-slot-num = <0x02>;
			dai-tdm-slot-width = <0x20>;
			phandle = <0x76>;
		};

		simple-audio-card,codec {
			sound-dai = <0x78>;
			clocks = <0x02 0xb4>;
		};
	};

	sound-ak4458 {
		compatible = "fsl,imx-audio-card";
		model = "ak4458-audio";

		pri-dai-link {
			link-name = "akcodec";
			format = "i2s";
			fsl,mclk-equal-bclk;

			cpu {
				sound-dai = <0x79>;
			};

			codec {
				sound-dai = <0x7a 0x7b>;
			};
		};
	};

	sound-ak5558 {
		compatible = "fsl,imx-audio-card";
		model = "ak5558-audio";
		status = "disabled";

		pri-dai-link {
			link-name = "akcodec";
			format = "i2s";
			fsl,mclk-equal-bclk;

			cpu {
				sound-dai = <0x7c>;
			};

			codec {
				sound-dai = <0x7d>;
			};
		};
	};

	sound-ak4497 {
		compatible = "fsl,imx-audio-card";
		model = "ak4497-audio";
		status = "disabled";

		pri-dai-link {
			link-name = "akcodec";
			format = "i2s";
			fsl,mclk-equal-bclk;

			cpu {
				sound-dai = <0x79>;
			};

			codec {
				sound-dai = <0x7e>;
			};
		};
	};

	sound-spdif {
		compatible = "fsl,imx-audio-spdif";
		model = "imx-spdif";
		spdif-controller = <0x7f>;
		spdif-out;
		spdif-in;
	};

	sound-micfil {
		compatible = "fsl,imx-audio-card";
		model = "micfil-audio";

		pri-dai-link {
			link-name = "micfil hifi";
			format = "i2s";

			cpu {
				sound-dai = <0x80>;
			};
		};
	};

	regulator-usdhc1 {
		compatible = "regulator-fixed";
		regulator-name = "WLAN_EN";
		pinctrl-names = "default";
		pinctrl-0 = <0x81>;
		regulator-min-microvolt = <0x325aa0>;
		regulator-max-microvolt = <0x325aa0>;
		gpio = <0x34 0x0a 0x00>;
		enable-active-high;
		phandle = <0x41>;
	};
};
